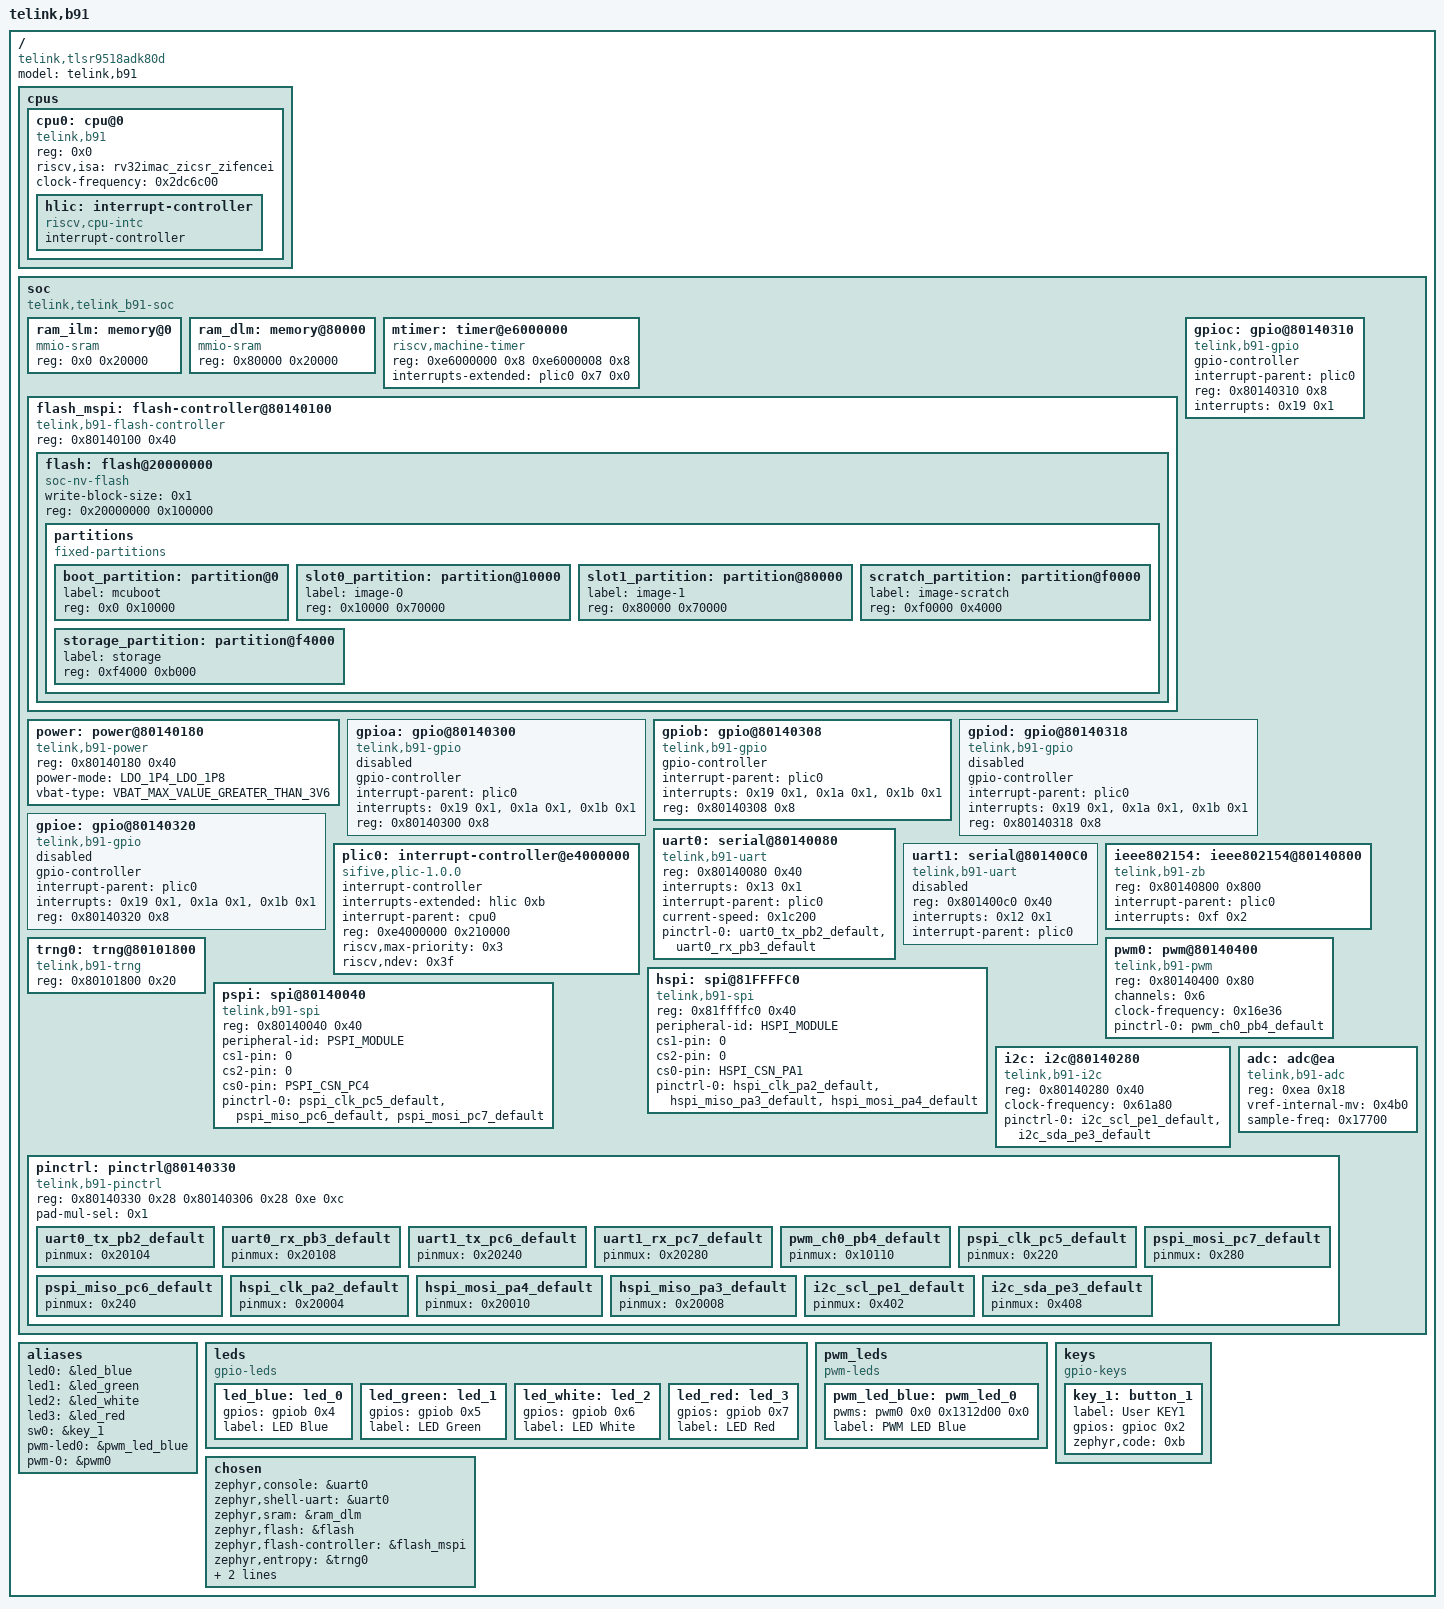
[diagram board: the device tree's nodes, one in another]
/dts-v1/;

/* node '/' defined in zephyr/dts/riscv/telink/telink_b91.dtsi:15 */
/ {
	#address-cells = < 0x1 >;             /* in zephyr/dts/riscv/telink/telink_b91.dtsi:16 */
	#size-cells = < 0x1 >;                /* in zephyr/dts/riscv/telink/telink_b91.dtsi:17 */
	model = "telink,b91";                 /* in zephyr/boards/telink/tlsr9518adk80d/tlsr9518adk80d.dts:15 */
	compatible = "telink,tlsr9518adk80d"; /* in zephyr/boards/telink/tlsr9518adk80d/tlsr9518adk80d.dts:16 */

	/* node '/cpus' defined in zephyr/dts/riscv/telink/telink_b91.dtsi:19 */
	cpus {
		#address-cells = < 0x1 >; /* in zephyr/dts/riscv/telink/telink_b91.dtsi:20 */
		#size-cells = < 0x0 >;    /* in zephyr/dts/riscv/telink/telink_b91.dtsi:21 */

		/* node '/cpus/cpu@0' defined in zephyr/dts/riscv/telink/telink_b91.dtsi:23 */
		cpu0: cpu@0 {
			reg = < 0x0 >;                         /* in zephyr/dts/riscv/telink/telink_b91.dtsi:24 */
			compatible = "telink,b91",
			             "andestech,andescore-v5",
			             "riscv";                  /* in zephyr/dts/riscv/telink/telink_b91.dtsi:26 */
			riscv,isa = "rv32imac_zicsr_zifencei"; /* in zephyr/dts/riscv/telink/telink_b91.dtsi:27 */
			clock-frequency = < 0x2dc6c00 >;       /* in zephyr/boards/telink/tlsr9518adk80d/tlsr9518adk80d.dts:84 */
			phandle = < 0x3 >;                     /* in zephyr/dts/riscv/telink/telink_b91.dtsi:136 */

			/* node '/cpus/cpu@0/interrupt-controller' defined in zephyr/dts/riscv/telink/telink_b91.dtsi:29 */
			hlic: interrupt-controller {
				compatible = "riscv,cpu-intc"; /* in zephyr/dts/riscv/telink/telink_b91.dtsi:30 */
				#address-cells = < 0x0 >;      /* in zephyr/dts/riscv/telink/telink_b91.dtsi:31 */
				#interrupt-cells = < 0x1 >;    /* in zephyr/dts/riscv/telink/telink_b91.dtsi:32 */
				interrupt-controller;          /* in zephyr/dts/riscv/telink/telink_b91.dtsi:33 */
				phandle = < 0x2 >;             /* in zephyr/dts/riscv/telink/telink_b91.dtsi:135 */
			};
		};
	};

	/* node '/soc' defined in zephyr/dts/riscv/telink/telink_b91.dtsi:38 */
	soc {
		#address-cells = < 0x1 >;             /* in zephyr/dts/riscv/telink/telink_b91.dtsi:39 */
		#size-cells = < 0x1 >;                /* in zephyr/dts/riscv/telink/telink_b91.dtsi:40 */
		compatible = "telink,telink_b91-soc"; /* in zephyr/dts/riscv/telink/telink_b91.dtsi:41 */
		ranges;                               /* in zephyr/dts/riscv/telink/telink_b91.dtsi:42 */

		/* node '/soc/memory@0' defined in zephyr/dts/riscv/telink/telink_b91.dtsi:44 */
		ram_ilm: memory@0 {
			compatible = "mmio-sram"; /* in zephyr/dts/riscv/telink/telink_b91.dtsi:45 */
			reg = < 0x0 0x20000 >;    /* in zephyr/boards/telink/tlsr9518adk80d/tlsr9518adk80d.dts:88 */
		};

		/* node '/soc/memory@80000' defined in zephyr/dts/riscv/telink/telink_b91.dtsi:48 */
		ram_dlm: memory@80000 {
			compatible = "mmio-sram";  /* in zephyr/dts/riscv/telink/telink_b91.dtsi:49 */
			reg = < 0x80000 0x20000 >; /* in zephyr/boards/telink/tlsr9518adk80d/tlsr9518adk80d.dts:92 */
		};

		/* node '/soc/timer@e6000000' defined in zephyr/dts/riscv/telink/telink_b91.dtsi:52 */
		mtimer: timer@e6000000 {
			compatible = "riscv,machine-timer";       /* in zephyr/dts/riscv/telink/telink_b91.dtsi:53 */
			reg = < 0xe6000000 0x8 0xe6000008 0x8 >;  /* in zephyr/dts/riscv/telink/telink_b91.dtsi:54 */
			reg-names = "mtime",
			            "mtimecmp";                   /* in zephyr/dts/riscv/telink/telink_b91.dtsi:55 */
			interrupts-extended = < &plic0 0x7 0x0 >; /* in zephyr/dts/riscv/telink/telink_b91.dtsi:56 */
		};

		/* node '/soc/flash-controller@80140100' defined in zephyr/dts/riscv/telink/telink_b91.dtsi:59 */
		flash_mspi: flash-controller@80140100 {
			compatible = "telink,b91-flash-controller"; /* in zephyr/dts/riscv/telink/telink_b91.dtsi:60 */
			reg = < 0x80140100 0x40 >;                  /* in zephyr/dts/riscv/telink/telink_b91.dtsi:61 */
			#address-cells = < 0x1 >;                   /* in zephyr/dts/riscv/telink/telink_b91.dtsi:63 */
			#size-cells = < 0x1 >;                      /* in zephyr/dts/riscv/telink/telink_b91.dtsi:64 */

			/* node '/soc/flash-controller@80140100/flash@20000000' defined in zephyr/dts/riscv/telink/telink_b91.dtsi:66 */
			flash: flash@20000000 {
				compatible = "soc-nv-flash";   /* in zephyr/dts/riscv/telink/telink_b91.dtsi:67 */
				write-block-size = < 0x1 >;    /* in zephyr/dts/riscv/telink/telink_b91.dtsi:68 */
				reg = < 0x20000000 0x100000 >; /* in zephyr/boards/telink/tlsr9518adk80d/tlsr9518adk80d.dts:96 */

				/* node '/soc/flash-controller@80140100/flash@20000000/partitions' defined in zephyr/boards/telink/tlsr9518adk80d/tlsr9518adk80d.dts:98 */
				partitions {
					compatible = "fixed-partitions"; /* in zephyr/boards/telink/tlsr9518adk80d/tlsr9518adk80d.dts:99 */
					#address-cells = < 0x1 >;        /* in zephyr/boards/telink/tlsr9518adk80d/tlsr9518adk80d.dts:100 */
					#size-cells = < 0x1 >;           /* in zephyr/boards/telink/tlsr9518adk80d/tlsr9518adk80d.dts:101 */

					/* node '/soc/flash-controller@80140100/flash@20000000/partitions/partition@0' defined in zephyr/boards/telink/tlsr9518adk80d/tlsr9518adk80d.dts:103 */
					boot_partition: partition@0 {
						label = "mcuboot";     /* in zephyr/boards/telink/tlsr9518adk80d/tlsr9518adk80d.dts:104 */
						reg = < 0x0 0x10000 >; /* in zephyr/boards/telink/tlsr9518adk80d/tlsr9518adk80d.dts:105 */
					};

					/* node '/soc/flash-controller@80140100/flash@20000000/partitions/partition@10000' defined in zephyr/boards/telink/tlsr9518adk80d/tlsr9518adk80d.dts:108 */
					slot0_partition: partition@10000 {
						label = "image-0";         /* in zephyr/boards/telink/tlsr9518adk80d/tlsr9518adk80d.dts:109 */
						reg = < 0x10000 0x70000 >; /* in zephyr/boards/telink/tlsr9518adk80d/tlsr9518adk80d.dts:110 */
					};

					/* node '/soc/flash-controller@80140100/flash@20000000/partitions/partition@80000' defined in zephyr/boards/telink/tlsr9518adk80d/tlsr9518adk80d.dts:113 */
					slot1_partition: partition@80000 {
						label = "image-1";         /* in zephyr/boards/telink/tlsr9518adk80d/tlsr9518adk80d.dts:114 */
						reg = < 0x80000 0x70000 >; /* in zephyr/boards/telink/tlsr9518adk80d/tlsr9518adk80d.dts:115 */
					};

					/* node '/soc/flash-controller@80140100/flash@20000000/partitions/partition@f0000' defined in zephyr/boards/telink/tlsr9518adk80d/tlsr9518adk80d.dts:118 */
					scratch_partition: partition@f0000 {
						label = "image-scratch";  /* in zephyr/boards/telink/tlsr9518adk80d/tlsr9518adk80d.dts:119 */
						reg = < 0xf0000 0x4000 >; /* in zephyr/boards/telink/tlsr9518adk80d/tlsr9518adk80d.dts:120 */
					};

					/* node '/soc/flash-controller@80140100/flash@20000000/partitions/partition@f4000' defined in zephyr/boards/telink/tlsr9518adk80d/tlsr9518adk80d.dts:123 */
					storage_partition: partition@f4000 {
						label = "storage";        /* in zephyr/boards/telink/tlsr9518adk80d/tlsr9518adk80d.dts:124 */
						reg = < 0xf4000 0xb000 >; /* in zephyr/boards/telink/tlsr9518adk80d/tlsr9518adk80d.dts:125 */
					};
				};
			};
		};

		/* node '/soc/power@80140180' defined in zephyr/dts/riscv/telink/telink_b91.dtsi:72 */
		power: power@80140180 {
			compatible = "telink,b91-power";               /* in zephyr/dts/riscv/telink/telink_b91.dtsi:73 */
			reg = < 0x80140180 0x40 >;                     /* in zephyr/dts/riscv/telink/telink_b91.dtsi:74 */
			power-mode = "LDO_1P4_LDO_1P8";                /* in zephyr/dts/riscv/telink/telink_b91.dtsi:75 */
			vbat-type = "VBAT_MAX_VALUE_GREATER_THAN_3V6"; /* in zephyr/dts/riscv/telink/telink_b91.dtsi:76 */
			status = "okay";                               /* in zephyr/dts/riscv/telink/telink_b91.dtsi:77 */
		};

		/* node '/soc/gpio@80140300' defined in zephyr/dts/riscv/telink/telink_b91.dtsi:80 */
		gpioa: gpio@80140300 {
			compatible = "telink,b91-gpio"; /* in zephyr/dts/riscv/telink/telink_b91.dtsi:81 */
			gpio-controller;                /* in zephyr/dts/riscv/telink/telink_b91.dtsi:82 */
			interrupt-parent = < &plic0 >;  /* in zephyr/dts/riscv/telink/telink_b91.dtsi:83 */
			interrupts = < 0x19 0x1 >,
			             < 0x1a 0x1 >,
			             < 0x1b 0x1 >;      /* in zephyr/dts/riscv/telink/telink_b91.dtsi:84 */
			reg = < 0x80140300 0x8 >;       /* in zephyr/dts/riscv/telink/telink_b91.dtsi:85 */
			status = "disabled";            /* in zephyr/dts/riscv/telink/telink_b91.dtsi:86 */
			#gpio-cells = < 0x2 >;          /* in zephyr/dts/riscv/telink/telink_b91.dtsi:87 */
		};

		/* node '/soc/gpio@80140308' defined in zephyr/dts/riscv/telink/telink_b91.dtsi:90 */
		gpiob: gpio@80140308 {
			compatible = "telink,b91-gpio"; /* in zephyr/dts/riscv/telink/telink_b91.dtsi:91 */
			gpio-controller;                /* in zephyr/dts/riscv/telink/telink_b91.dtsi:92 */
			interrupt-parent = < &plic0 >;  /* in zephyr/dts/riscv/telink/telink_b91.dtsi:93 */
			interrupts = < 0x19 0x1 >,
			             < 0x1a 0x1 >,
			             < 0x1b 0x1 >;      /* in zephyr/dts/riscv/telink/telink_b91.dtsi:94 */
			reg = < 0x80140308 0x8 >;       /* in zephyr/dts/riscv/telink/telink_b91.dtsi:95 */
			#gpio-cells = < 0x2 >;          /* in zephyr/dts/riscv/telink/telink_b91.dtsi:97 */
			status = "okay";                /* in zephyr/boards/telink/tlsr9518adk80d/tlsr9518adk80d.dts:132 */
			phandle = < 0xf >;              /* in zephyr/boards/telink/tlsr9518adk80d/tlsr9518adk80d.dts:32 */
		};

		/* node '/soc/gpio@80140310' defined in zephyr/dts/riscv/telink/telink_b91.dtsi:100 */
		gpioc: gpio@80140310 {
			compatible = "telink,b91-gpio"; /* in zephyr/dts/riscv/telink/telink_b91.dtsi:101 */
			gpio-controller;                /* in zephyr/dts/riscv/telink/telink_b91.dtsi:102 */
			interrupt-parent = < &plic0 >;  /* in zephyr/dts/riscv/telink/telink_b91.dtsi:103 */
			reg = < 0x80140310 0x8 >;       /* in zephyr/dts/riscv/telink/telink_b91.dtsi:105 */
			#gpio-cells = < 0x2 >;          /* in zephyr/dts/riscv/telink/telink_b91.dtsi:107 */
			interrupts = < 0x19 0x1 >;      /* in zephyr/boards/telink/tlsr9518adk80d/tlsr9518adk80d.dts:136 */
			status = "okay";                /* in zephyr/boards/telink/tlsr9518adk80d/tlsr9518adk80d.dts:137 */
			phandle = < 0x11 >;             /* in zephyr/boards/telink/tlsr9518adk80d/tlsr9518adk80d.dts:66 */
		};

		/* node '/soc/gpio@80140318' defined in zephyr/dts/riscv/telink/telink_b91.dtsi:110 */
		gpiod: gpio@80140318 {
			compatible = "telink,b91-gpio"; /* in zephyr/dts/riscv/telink/telink_b91.dtsi:111 */
			gpio-controller;                /* in zephyr/dts/riscv/telink/telink_b91.dtsi:112 */
			interrupt-parent = < &plic0 >;  /* in zephyr/dts/riscv/telink/telink_b91.dtsi:113 */
			interrupts = < 0x19 0x1 >,
			             < 0x1a 0x1 >,
			             < 0x1b 0x1 >;      /* in zephyr/dts/riscv/telink/telink_b91.dtsi:114 */
			reg = < 0x80140318 0x8 >;       /* in zephyr/dts/riscv/telink/telink_b91.dtsi:115 */
			status = "disabled";            /* in zephyr/dts/riscv/telink/telink_b91.dtsi:116 */
			#gpio-cells = < 0x2 >;          /* in zephyr/dts/riscv/telink/telink_b91.dtsi:117 */
		};

		/* node '/soc/gpio@80140320' defined in zephyr/dts/riscv/telink/telink_b91.dtsi:120 */
		gpioe: gpio@80140320 {
			compatible = "telink,b91-gpio"; /* in zephyr/dts/riscv/telink/telink_b91.dtsi:121 */
			gpio-controller;                /* in zephyr/dts/riscv/telink/telink_b91.dtsi:122 */
			interrupt-parent = < &plic0 >;  /* in zephyr/dts/riscv/telink/telink_b91.dtsi:123 */
			interrupts = < 0x19 0x1 >,
			             < 0x1a 0x1 >,
			             < 0x1b 0x1 >;      /* in zephyr/dts/riscv/telink/telink_b91.dtsi:124 */
			reg = < 0x80140320 0x8 >;       /* in zephyr/dts/riscv/telink/telink_b91.dtsi:125 */
			status = "disabled";            /* in zephyr/dts/riscv/telink/telink_b91.dtsi:126 */
			#gpio-cells = < 0x2 >;          /* in zephyr/dts/riscv/telink/telink_b91.dtsi:127 */
		};

		/* node '/soc/interrupt-controller@e4000000' defined in zephyr/dts/riscv/telink/telink_b91.dtsi:130 */
		plic0: interrupt-controller@e4000000 {
			compatible = "sifive,plic-1.0.0";    /* in zephyr/dts/riscv/telink/telink_b91.dtsi:131 */
			#address-cells = < 0x0 >;            /* in zephyr/dts/riscv/telink/telink_b91.dtsi:132 */
			#interrupt-cells = < 0x2 >;          /* in zephyr/dts/riscv/telink/telink_b91.dtsi:133 */
			interrupt-controller;                /* in zephyr/dts/riscv/telink/telink_b91.dtsi:134 */
			interrupts-extended = < &hlic 0xb >; /* in zephyr/dts/riscv/telink/telink_b91.dtsi:135 */
			interrupt-parent = < &cpu0 >;        /* in zephyr/dts/riscv/telink/telink_b91.dtsi:136 */
			reg = < 0xe4000000 0x210000 >;       /* in zephyr/dts/riscv/telink/telink_b91.dtsi:137 */
			riscv,max-priority = < 0x3 >;        /* in zephyr/dts/riscv/telink/telink_b91.dtsi:138 */
			riscv,ndev = < 0x3f >;               /* in zephyr/dts/riscv/telink/telink_b91.dtsi:139 */
			phandle = < 0x1 >;                   /* in zephyr/dts/riscv/telink/telink_b91.dtsi:56 */
		};

		/* node '/soc/serial@80140080' defined in zephyr/dts/riscv/telink/telink_b91.dtsi:142 */
		uart0: serial@80140080 {
			compatible = "telink,b91-uart";                              /* in zephyr/dts/riscv/telink/telink_b91.dtsi:143 */
			reg = < 0x80140080 0x40 >;                                   /* in zephyr/dts/riscv/telink/telink_b91.dtsi:144 */
			interrupts = < 0x13 0x1 >;                                   /* in zephyr/dts/riscv/telink/telink_b91.dtsi:145 */
			interrupt-parent = < &plic0 >;                               /* in zephyr/dts/riscv/telink/telink_b91.dtsi:146 */
			status = "okay";                                             /* in zephyr/boards/telink/tlsr9518adk80d/tlsr9518adk80d.dts:141 */
			current-speed = < 0x1c200 >;                                 /* in zephyr/boards/telink/tlsr9518adk80d/tlsr9518adk80d.dts:142 */
			pinctrl-0 = < &uart0_tx_pb2_default &uart0_rx_pb3_default >; /* in zephyr/boards/telink/tlsr9518adk80d/tlsr9518adk80d.dts:143 */
			pinctrl-names = "default";                                   /* in zephyr/boards/telink/tlsr9518adk80d/tlsr9518adk80d.dts:144 */
		};

		/* node '/soc/serial@801400C0' defined in zephyr/dts/riscv/telink/telink_b91.dtsi:150 */
		uart1: serial@801400C0 {
			compatible = "telink,b91-uart"; /* in zephyr/dts/riscv/telink/telink_b91.dtsi:151 */
			reg = < 0x801400c0 0x40 >;      /* in zephyr/dts/riscv/telink/telink_b91.dtsi:152 */
			interrupts = < 0x12 0x1 >;      /* in zephyr/dts/riscv/telink/telink_b91.dtsi:153 */
			interrupt-parent = < &plic0 >;  /* in zephyr/dts/riscv/telink/telink_b91.dtsi:154 */
			status = "disabled";            /* in zephyr/dts/riscv/telink/telink_b91.dtsi:155 */
		};

		/* node '/soc/ieee802154@80140800' defined in zephyr/dts/riscv/telink/telink_b91.dtsi:158 */
		ieee802154: ieee802154@80140800 {
			compatible = "telink,b91-zb";  /* in zephyr/dts/riscv/telink/telink_b91.dtsi:159 */
			reg = < 0x80140800 0x800 >;    /* in zephyr/dts/riscv/telink/telink_b91.dtsi:160 */
			interrupt-parent = < &plic0 >; /* in zephyr/dts/riscv/telink/telink_b91.dtsi:161 */
			interrupts = < 0xf 0x2 >;      /* in zephyr/dts/riscv/telink/telink_b91.dtsi:162 */
			status = "okay";               /* in zephyr/boards/telink/tlsr9518adk80d/tlsr9518adk80d.dts:152 */
		};

		/* node '/soc/trng@80101800' defined in zephyr/dts/riscv/telink/telink_b91.dtsi:166 */
		trng0: trng@80101800 {
			compatible = "telink,b91-trng"; /* in zephyr/dts/riscv/telink/telink_b91.dtsi:167 */
			reg = < 0x80101800 0x20 >;      /* in zephyr/dts/riscv/telink/telink_b91.dtsi:168 */
			status = "okay";                /* in zephyr/boards/telink/tlsr9518adk80d/tlsr9518adk80d.dts:148 */
		};

		/* node '/soc/pwm@80140400' defined in zephyr/dts/riscv/telink/telink_b91.dtsi:172 */
		pwm0: pwm@80140400 {
			compatible = "telink,b91-pwm";        /* in zephyr/dts/riscv/telink/telink_b91.dtsi:173 */
			reg = < 0x80140400 0x80 >;            /* in zephyr/dts/riscv/telink/telink_b91.dtsi:174 */
			channels = < 0x6 >;                   /* in zephyr/dts/riscv/telink/telink_b91.dtsi:175 */
			#pwm-cells = < 0x3 >;                 /* in zephyr/dts/riscv/telink/telink_b91.dtsi:177 */
			status = "okay";                      /* in zephyr/boards/telink/tlsr9518adk80d/tlsr9518adk80d.dts:156 */
			clock-frequency = < 0x16e36 >;        /* in zephyr/boards/telink/tlsr9518adk80d/tlsr9518adk80d.dts:157 */
			pinctrl-0 = < &pwm_ch0_pb4_default >; /* in zephyr/boards/telink/tlsr9518adk80d/tlsr9518adk80d.dts:158 */
			pinctrl-names = "default";            /* in zephyr/boards/telink/tlsr9518adk80d/tlsr9518adk80d.dts:159 */
			phandle = < 0x10 >;                   /* in zephyr/boards/telink/tlsr9518adk80d/tlsr9518adk80d.dts:56 */
		};

		/* node '/soc/spi@81FFFFC0' defined in zephyr/dts/riscv/telink/telink_b91.dtsi:180 */
		hspi: spi@81FFFFC0 {
			compatible = "telink,b91-spi";                                                       /* in zephyr/dts/riscv/telink/telink_b91.dtsi:181 */
			reg = < 0x81ffffc0 0x40 >;                                                           /* in zephyr/dts/riscv/telink/telink_b91.dtsi:182 */
			peripheral-id = "HSPI_MODULE";                                                       /* in zephyr/dts/riscv/telink/telink_b91.dtsi:183 */
			cs1-pin = "0";                                                                       /* in zephyr/dts/riscv/telink/telink_b91.dtsi:185 */
			cs2-pin = "0";                                                                       /* in zephyr/dts/riscv/telink/telink_b91.dtsi:186 */
			#address-cells = < 0x1 >;                                                            /* in zephyr/dts/riscv/telink/telink_b91.dtsi:187 */
			#size-cells = < 0x0 >;                                                               /* in zephyr/dts/riscv/telink/telink_b91.dtsi:188 */
			status = "okay";                                                                     /* in zephyr/boards/telink/tlsr9518adk80d/tlsr9518adk80d.dts:170 */
			cs0-pin = "HSPI_CSN_PA1";                                                            /* in zephyr/boards/telink/tlsr9518adk80d/tlsr9518adk80d.dts:171 */
			pinctrl-0 = < &hspi_clk_pa2_default &hspi_miso_pa3_default &hspi_mosi_pa4_default >; /* in zephyr/boards/telink/tlsr9518adk80d/tlsr9518adk80d.dts:172 */
			pinctrl-names = "default";                                                           /* in zephyr/boards/telink/tlsr9518adk80d/tlsr9518adk80d.dts:173 */
		};

		/* node '/soc/spi@80140040' defined in zephyr/dts/riscv/telink/telink_b91.dtsi:192 */
		pspi: spi@80140040 {
			compatible = "telink,b91-spi";                                                       /* in zephyr/dts/riscv/telink/telink_b91.dtsi:193 */
			reg = < 0x80140040 0x40 >;                                                           /* in zephyr/dts/riscv/telink/telink_b91.dtsi:194 */
			peripheral-id = "PSPI_MODULE";                                                       /* in zephyr/dts/riscv/telink/telink_b91.dtsi:195 */
			cs1-pin = "0";                                                                       /* in zephyr/dts/riscv/telink/telink_b91.dtsi:197 */
			cs2-pin = "0";                                                                       /* in zephyr/dts/riscv/telink/telink_b91.dtsi:198 */
			#address-cells = < 0x1 >;                                                            /* in zephyr/dts/riscv/telink/telink_b91.dtsi:199 */
			#size-cells = < 0x0 >;                                                               /* in zephyr/dts/riscv/telink/telink_b91.dtsi:200 */
			status = "okay";                                                                     /* in zephyr/boards/telink/tlsr9518adk80d/tlsr9518adk80d.dts:163 */
			cs0-pin = "PSPI_CSN_PC4";                                                            /* in zephyr/boards/telink/tlsr9518adk80d/tlsr9518adk80d.dts:164 */
			pinctrl-0 = < &pspi_clk_pc5_default &pspi_miso_pc6_default &pspi_mosi_pc7_default >; /* in zephyr/boards/telink/tlsr9518adk80d/tlsr9518adk80d.dts:165 */
			pinctrl-names = "default";                                                           /* in zephyr/boards/telink/tlsr9518adk80d/tlsr9518adk80d.dts:166 */
		};

		/* node '/soc/i2c@80140280' defined in zephyr/dts/riscv/telink/telink_b91.dtsi:204 */
		i2c: i2c@80140280 {
			compatible = "telink,b91-i2c";                             /* in zephyr/dts/riscv/telink/telink_b91.dtsi:205 */
			reg = < 0x80140280 0x40 >;                                 /* in zephyr/dts/riscv/telink/telink_b91.dtsi:206 */
			#address-cells = < 0x1 >;                                  /* in zephyr/dts/riscv/telink/telink_b91.dtsi:207 */
			#size-cells = < 0x0 >;                                     /* in zephyr/dts/riscv/telink/telink_b91.dtsi:208 */
			status = "okay";                                           /* in zephyr/boards/telink/tlsr9518adk80d/tlsr9518adk80d.dts:177 */
			clock-frequency = < 0x61a80 >;                             /* in zephyr/boards/telink/tlsr9518adk80d/tlsr9518adk80d.dts:178 */
			pinctrl-0 = < &i2c_scl_pe1_default &i2c_sda_pe3_default >; /* in zephyr/boards/telink/tlsr9518adk80d/tlsr9518adk80d.dts:179 */
			pinctrl-names = "default";                                 /* in zephyr/boards/telink/tlsr9518adk80d/tlsr9518adk80d.dts:180 */
		};

		/* node '/soc/adc@ea' defined in zephyr/dts/riscv/telink/telink_b91.dtsi:213 */
		adc: adc@ea {
			compatible = "telink,b91-adc"; /* in zephyr/dts/riscv/telink/telink_b91.dtsi:214 */
			reg = < 0xea 0x18 >;           /* in zephyr/dts/riscv/telink/telink_b91.dtsi:215 */
			#io-channel-cells = < 0x1 >;   /* in zephyr/dts/riscv/telink/telink_b91.dtsi:217 */
			status = "okay";               /* in zephyr/boards/telink/tlsr9518adk80d/tlsr9518adk80d.dts:184 */
			vref-internal-mv = < 0x4b0 >;  /* in zephyr/boards/telink/tlsr9518adk80d/tlsr9518adk80d.dts:185 */
			sample-freq = < 0x17700 >;     /* in zephyr/boards/telink/tlsr9518adk80d/tlsr9518adk80d.dts:186 */
		};

		/* node '/soc/pinctrl@80140330' defined in zephyr/dts/riscv/telink/telink_b91.dtsi:220 */
		pinctrl: pinctrl@80140330 {
			compatible = "telink,b91-pinctrl";                 /* in zephyr/dts/riscv/telink/telink_b91.dtsi:221 */
			reg = < 0x80140330 0x28 0x80140306 0x28 0xe 0xc >; /* in zephyr/dts/riscv/telink/telink_b91.dtsi:222 */
			reg-names = "pin_mux",
			            "gpio_en",
			            "pull_up_en";                          /* in zephyr/dts/riscv/telink/telink_b91.dtsi:225 */
			status = "okay";                                   /* in zephyr/dts/riscv/telink/telink_b91.dtsi:228 */
			pad-mul-sel = < 0x1 >;                             /* in zephyr/boards/telink/tlsr9518adk80d/tlsr9518adk80d-pinctrl.dtsi:13 */

			/* node '/soc/pinctrl@80140330/uart0_tx_pb2_default' defined in zephyr/boards/telink/tlsr9518adk80d/tlsr9518adk80d-pinctrl.dtsi:17 */
			uart0_tx_pb2_default: uart0_tx_pb2_default {
				pinmux = < 0x20104 >; /* in zephyr/boards/telink/tlsr9518adk80d/tlsr9518adk80d-pinctrl.dtsi:18 */
				phandle = < 0x4 >;    /* in zephyr/boards/telink/tlsr9518adk80d/tlsr9518adk80d.dts:143 */
			};

			/* node '/soc/pinctrl@80140330/uart0_rx_pb3_default' defined in zephyr/boards/telink/tlsr9518adk80d/tlsr9518adk80d-pinctrl.dtsi:21 */
			uart0_rx_pb3_default: uart0_rx_pb3_default {
				pinmux = < 0x20108 >; /* in zephyr/boards/telink/tlsr9518adk80d/tlsr9518adk80d-pinctrl.dtsi:22 */
				phandle = < 0x5 >;    /* in zephyr/boards/telink/tlsr9518adk80d/tlsr9518adk80d.dts:143 */
			};

			/* node '/soc/pinctrl@80140330/uart1_tx_pc6_default' defined in zephyr/boards/telink/tlsr9518adk80d/tlsr9518adk80d-pinctrl.dtsi:27 */
			uart1_tx_pc6_default: uart1_tx_pc6_default {
				pinmux = < 0x20240 >; /* in zephyr/boards/telink/tlsr9518adk80d/tlsr9518adk80d-pinctrl.dtsi:28 */
			};

			/* node '/soc/pinctrl@80140330/uart1_rx_pc7_default' defined in zephyr/boards/telink/tlsr9518adk80d/tlsr9518adk80d-pinctrl.dtsi:31 */
			uart1_rx_pc7_default: uart1_rx_pc7_default {
				pinmux = < 0x20280 >; /* in zephyr/boards/telink/tlsr9518adk80d/tlsr9518adk80d-pinctrl.dtsi:32 */
			};

			/* node '/soc/pinctrl@80140330/pwm_ch0_pb4_default' defined in zephyr/boards/telink/tlsr9518adk80d/tlsr9518adk80d-pinctrl.dtsi:37 */
			pwm_ch0_pb4_default: pwm_ch0_pb4_default {
				pinmux = < 0x10110 >; /* in zephyr/boards/telink/tlsr9518adk80d/tlsr9518adk80d-pinctrl.dtsi:38 */
				phandle = < 0x6 >;    /* in zephyr/boards/telink/tlsr9518adk80d/tlsr9518adk80d.dts:158 */
			};

			/* node '/soc/pinctrl@80140330/pspi_clk_pc5_default' defined in zephyr/boards/telink/tlsr9518adk80d/tlsr9518adk80d-pinctrl.dtsi:43 */
			pspi_clk_pc5_default: pspi_clk_pc5_default {
				pinmux = < 0x220 >; /* in zephyr/boards/telink/tlsr9518adk80d/tlsr9518adk80d-pinctrl.dtsi:44 */
				phandle = < 0xa >;  /* in zephyr/boards/telink/tlsr9518adk80d/tlsr9518adk80d.dts:165 */
			};

			/* node '/soc/pinctrl@80140330/pspi_mosi_pc7_default' defined in zephyr/boards/telink/tlsr9518adk80d/tlsr9518adk80d-pinctrl.dtsi:47 */
			pspi_mosi_pc7_default: pspi_mosi_pc7_default {
				pinmux = < 0x280 >; /* in zephyr/boards/telink/tlsr9518adk80d/tlsr9518adk80d-pinctrl.dtsi:48 */
				phandle = < 0xc >;  /* in zephyr/boards/telink/tlsr9518adk80d/tlsr9518adk80d.dts:165 */
			};

			/* node '/soc/pinctrl@80140330/pspi_miso_pc6_default' defined in zephyr/boards/telink/tlsr9518adk80d/tlsr9518adk80d-pinctrl.dtsi:51 */
			pspi_miso_pc6_default: pspi_miso_pc6_default {
				pinmux = < 0x240 >; /* in zephyr/boards/telink/tlsr9518adk80d/tlsr9518adk80d-pinctrl.dtsi:52 */
				phandle = < 0xb >;  /* in zephyr/boards/telink/tlsr9518adk80d/tlsr9518adk80d.dts:165 */
			};

			/* node '/soc/pinctrl@80140330/hspi_clk_pa2_default' defined in zephyr/boards/telink/tlsr9518adk80d/tlsr9518adk80d-pinctrl.dtsi:57 */
			hspi_clk_pa2_default: hspi_clk_pa2_default {
				pinmux = < 0x20004 >; /* in zephyr/boards/telink/tlsr9518adk80d/tlsr9518adk80d-pinctrl.dtsi:58 */
				phandle = < 0x7 >;    /* in zephyr/boards/telink/tlsr9518adk80d/tlsr9518adk80d.dts:172 */
			};

			/* node '/soc/pinctrl@80140330/hspi_mosi_pa4_default' defined in zephyr/boards/telink/tlsr9518adk80d/tlsr9518adk80d-pinctrl.dtsi:61 */
			hspi_mosi_pa4_default: hspi_mosi_pa4_default {
				pinmux = < 0x20010 >; /* in zephyr/boards/telink/tlsr9518adk80d/tlsr9518adk80d-pinctrl.dtsi:62 */
				phandle = < 0x9 >;    /* in zephyr/boards/telink/tlsr9518adk80d/tlsr9518adk80d.dts:172 */
			};

			/* node '/soc/pinctrl@80140330/hspi_miso_pa3_default' defined in zephyr/boards/telink/tlsr9518adk80d/tlsr9518adk80d-pinctrl.dtsi:65 */
			hspi_miso_pa3_default: hspi_miso_pa3_default {
				pinmux = < 0x20008 >; /* in zephyr/boards/telink/tlsr9518adk80d/tlsr9518adk80d-pinctrl.dtsi:66 */
				phandle = < 0x8 >;    /* in zephyr/boards/telink/tlsr9518adk80d/tlsr9518adk80d.dts:172 */
			};

			/* node '/soc/pinctrl@80140330/i2c_scl_pe1_default' defined in zephyr/boards/telink/tlsr9518adk80d/tlsr9518adk80d-pinctrl.dtsi:71 */
			i2c_scl_pe1_default: i2c_scl_pe1_default {
				pinmux = < 0x402 >; /* in zephyr/boards/telink/tlsr9518adk80d/tlsr9518adk80d-pinctrl.dtsi:72 */
				phandle = < 0xd >;  /* in zephyr/boards/telink/tlsr9518adk80d/tlsr9518adk80d.dts:179 */
			};

			/* node '/soc/pinctrl@80140330/i2c_sda_pe3_default' defined in zephyr/boards/telink/tlsr9518adk80d/tlsr9518adk80d-pinctrl.dtsi:75 */
			i2c_sda_pe3_default: i2c_sda_pe3_default {
				pinmux = < 0x408 >; /* in zephyr/boards/telink/tlsr9518adk80d/tlsr9518adk80d-pinctrl.dtsi:76 */
				phandle = < 0xe >;  /* in zephyr/boards/telink/tlsr9518adk80d/tlsr9518adk80d.dts:179 */
			};
		};
	};

	/* node '/aliases' defined in zephyr/boards/telink/tlsr9518adk80d/tlsr9518adk80d.dts:18 */
	aliases {
		led0 = &led_blue;         /* in zephyr/boards/telink/tlsr9518adk80d/tlsr9518adk80d.dts:19 */
		led1 = &led_green;        /* in zephyr/boards/telink/tlsr9518adk80d/tlsr9518adk80d.dts:20 */
		led2 = &led_white;        /* in zephyr/boards/telink/tlsr9518adk80d/tlsr9518adk80d.dts:21 */
		led3 = &led_red;          /* in zephyr/boards/telink/tlsr9518adk80d/tlsr9518adk80d.dts:22 */
		sw0 = &key_1;             /* in zephyr/boards/telink/tlsr9518adk80d/tlsr9518adk80d.dts:23 */
		pwm-led0 = &pwm_led_blue; /* in zephyr/boards/telink/tlsr9518adk80d/tlsr9518adk80d.dts:24 */
		pwm-0 = &pwm0;            /* in zephyr/boards/telink/tlsr9518adk80d/tlsr9518adk80d.dts:25 */
	};

	/* node '/leds' defined in zephyr/boards/telink/tlsr9518adk80d/tlsr9518adk80d.dts:28 */
	leds {
		compatible = "gpio-leds"; /* in zephyr/boards/telink/tlsr9518adk80d/tlsr9518adk80d.dts:29 */

		/* node '/leds/led_0' defined in zephyr/boards/telink/tlsr9518adk80d/tlsr9518adk80d.dts:31 */
		led_blue: led_0 {
			gpios = < &gpiob 0x4 0x0 >; /* in zephyr/boards/telink/tlsr9518adk80d/tlsr9518adk80d.dts:32 */
			label = "LED Blue";         /* in zephyr/boards/telink/tlsr9518adk80d/tlsr9518adk80d.dts:33 */
		};

		/* node '/leds/led_1' defined in zephyr/boards/telink/tlsr9518adk80d/tlsr9518adk80d.dts:36 */
		led_green: led_1 {
			gpios = < &gpiob 0x5 0x0 >; /* in zephyr/boards/telink/tlsr9518adk80d/tlsr9518adk80d.dts:37 */
			label = "LED Green";        /* in zephyr/boards/telink/tlsr9518adk80d/tlsr9518adk80d.dts:38 */
		};

		/* node '/leds/led_2' defined in zephyr/boards/telink/tlsr9518adk80d/tlsr9518adk80d.dts:41 */
		led_white: led_2 {
			gpios = < &gpiob 0x6 0x0 >; /* in zephyr/boards/telink/tlsr9518adk80d/tlsr9518adk80d.dts:42 */
			label = "LED White";        /* in zephyr/boards/telink/tlsr9518adk80d/tlsr9518adk80d.dts:43 */
		};

		/* node '/leds/led_3' defined in zephyr/boards/telink/tlsr9518adk80d/tlsr9518adk80d.dts:46 */
		led_red: led_3 {
			gpios = < &gpiob 0x7 0x0 >; /* in zephyr/boards/telink/tlsr9518adk80d/tlsr9518adk80d.dts:47 */
			label = "LED Red";          /* in zephyr/boards/telink/tlsr9518adk80d/tlsr9518adk80d.dts:48 */
		};
	};

	/* node '/pwm_leds' defined in zephyr/boards/telink/tlsr9518adk80d/tlsr9518adk80d.dts:52 */
	pwm_leds {
		compatible = "pwm-leds"; /* in zephyr/boards/telink/tlsr9518adk80d/tlsr9518adk80d.dts:53 */

		/* node '/pwm_leds/pwm_led_0' defined in zephyr/boards/telink/tlsr9518adk80d/tlsr9518adk80d.dts:55 */
		pwm_led_blue: pwm_led_0 {
			pwms = < &pwm0 0x0 0x1312d00 0x0 >; /* in zephyr/boards/telink/tlsr9518adk80d/tlsr9518adk80d.dts:56 */
			label = "PWM LED Blue";             /* in zephyr/boards/telink/tlsr9518adk80d/tlsr9518adk80d.dts:57 */
		};
	};

	/* node '/keys' defined in zephyr/boards/telink/tlsr9518adk80d/tlsr9518adk80d.dts:61 */
	keys {
		compatible = "gpio-keys"; /* in zephyr/boards/telink/tlsr9518adk80d/tlsr9518adk80d.dts:62 */

		/* node '/keys/button_1' defined in zephyr/boards/telink/tlsr9518adk80d/tlsr9518adk80d.dts:64 */
		key_1: button_1 {
			label = "User KEY1";         /* in zephyr/boards/telink/tlsr9518adk80d/tlsr9518adk80d.dts:65 */
			gpios = < &gpioc 0x2 0x20 >; /* in zephyr/boards/telink/tlsr9518adk80d/tlsr9518adk80d.dts:66 */
			zephyr,code = < 0xb >;       /* in zephyr/boards/telink/tlsr9518adk80d/tlsr9518adk80d.dts:67 */
		};
	};

	/* node '/chosen' defined in zephyr/boards/telink/tlsr9518adk80d/tlsr9518adk80d.dts:71 */
	chosen {
		zephyr,console = &uart0;                  /* in zephyr/boards/telink/tlsr9518adk80d/tlsr9518adk80d.dts:72 */
		zephyr,shell-uart = &uart0;               /* in zephyr/boards/telink/tlsr9518adk80d/tlsr9518adk80d.dts:73 */
		zephyr,sram = &ram_dlm;                   /* in zephyr/boards/telink/tlsr9518adk80d/tlsr9518adk80d.dts:74 */
		zephyr,flash = &flash;                    /* in zephyr/boards/telink/tlsr9518adk80d/tlsr9518adk80d.dts:75 */
		zephyr,flash-controller = &flash_mspi;    /* in zephyr/boards/telink/tlsr9518adk80d/tlsr9518adk80d.dts:76 */
		zephyr,entropy = &trng0;                  /* in zephyr/boards/telink/tlsr9518adk80d/tlsr9518adk80d.dts:77 */
		zephyr,code-partition = &slot0_partition; /* in zephyr/boards/telink/tlsr9518adk80d/tlsr9518adk80d.dts:78 */
		zephyr,ieee802154 = &ieee802154;          /* in zephyr/boards/telink/tlsr9518adk80d/tlsr9518adk80d.dts:79 */
	};
};
